VERSION "1.0"

NS_ :

BS_:

BU_: ECU1 ECU2

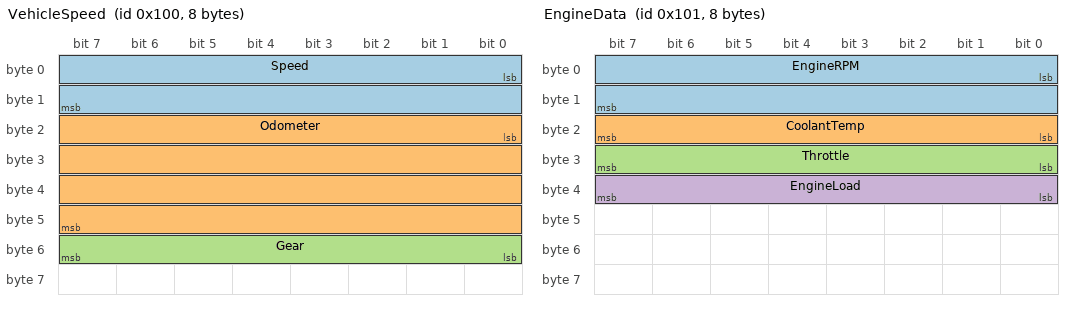
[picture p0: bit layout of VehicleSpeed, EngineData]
BO_ 256 VehicleSpeed: 8 ECU1
 SG_ Speed : 0|16@1+ (0.01,0) [0|655.35] "km/h" ECU2
 SG_ Odometer : 16|32@1+ (0.1,0) [0|429496729.5] "km" ECU2
 SG_ Gear : 48|8@1+ (1,0) [0|255] "" ECU2

BO_ 257 EngineData: 8 ECU1
 SG_ EngineRPM : 0|16@1+ (0.25,0) [0|16383.75] "rpm" ECU2
 SG_ CoolantTemp : 16|8@1- (1,-40) [-40|215] "degC" ECU2
 SG_ Throttle : 24|8@1+ (0.5,0) [0|127.5] "%" ECU2
 SG_ EngineLoad : 32|8@1+ (0.4,0) [0|102] "%" ECU2

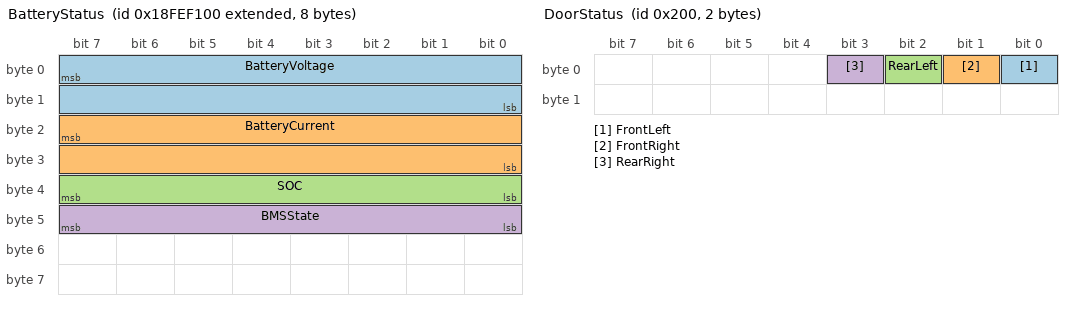
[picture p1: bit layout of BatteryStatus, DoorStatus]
BO_ 2566844672 BatteryStatus: 8 ECU1
 SG_ BatteryVoltage : 7|16@0+ (0.01,0) [0|655.35] "V" ECU2
 SG_ BatteryCurrent : 23|16@0- (0.1,0) [-3276.8|3276.7] "A" ECU2
 SG_ SOC : 32|8@1+ (1,0) [0|100] "%" ECU2
 SG_ BMSState : 40|8@1+ (1,0) [0|255] "" ECU2

BO_ 512 DoorStatus: 2 ECU1
 SG_ FrontLeft : 0|1@1+ (1,0) [0|1] "" ECU2
 SG_ FrontRight : 1|1@1+ (1,0) [0|1] "" ECU2
 SG_ RearLeft : 2|1@1+ (1,0) [0|1] "" ECU2
 SG_ RearRight : 3|1@1+ (1,0) [0|1] "" ECU2

BO_ 768 MuxExample: 8 ECU1
 SG_ Selector M : 0|8@1+ (1,0) [0|255] "" ECU2
 SG_ MuxA_Voltage m0 : 8|16@1+ (0.1,0) [0|6553.5] "V" ECU2
 SG_ MuxB_Count m1 : 8|16@1+ (1,0) [0|65535] "" ECU2

BO_ 1024 FdSensor: 12 ECU1
 SG_ FdValue : 0|32@1+ (0.001,0) [0|4294967.295] "V" ECU2
 SG_ FdCounter : 32|8@1+ (1,0) [0|255] "" ECU2

BO_ 1280 Fd64Array: 64 ECU1
 SG_ FD64_Ch00 : 0|8@1+ (1,0) [0|255] "" ECU2
 SG_ FD64_Ch01 : 8|8@1+ (1,0) [0|255] "" ECU2
 SG_ FD64_Ch02 : 16|8@1+ (1,0) [0|255] "" ECU2
 SG_ FD64_Ch03 : 24|8@1+ (1,0) [0|255] "" ECU2
 SG_ FD64_Ch04 : 32|8@1+ (1,0) [0|255] "" ECU2
 SG_ FD64_Ch05 : 40|8@1+ (1,0) [0|255] "" ECU2
 SG_ FD64_Ch06 : 48|8@1+ (1,0) [0|255] "" ECU2
 SG_ FD64_Ch07 : 56|8@1+ (1,0) [0|255] "" ECU2
 SG_ FD64_Ch08 : 64|8@1+ (1,0) [0|255] "" ECU2
 SG_ FD64_Ch09 : 72|8@1+ (1,0) [0|255] "" ECU2
 SG_ FD64_Ch10 : 80|8@1+ (1,0) [0|255] "" ECU2
 SG_ FD64_Ch11 : 88|8@1+ (1,0) [0|255] "" ECU2
 SG_ FD64_Ch12 : 96|8@1+ (1,0) [0|255] "" ECU2
 SG_ FD64_Ch13 : 104|8@1+ (1,0) [0|255] "" ECU2
 SG_ FD64_Ch14 : 112|8@1+ (1,0) [0|255] "" ECU2
 SG_ FD64_Ch15 : 120|8@1+ (1,0) [0|255] "" ECU2
 SG_ FD64_Ch16 : 128|8@1+ (1,0) [0|255] "" ECU2
 SG_ FD64_Ch17 : 136|8@1+ (1,0) [0|255] "" ECU2
 SG_ FD64_Ch18 : 144|8@1+ (1,0) [0|255] "" ECU2
 SG_ FD64_Ch19 : 152|8@1+ (1,0) [0|255] "" ECU2
 SG_ FD64_Ch20 : 160|8@1+ (1,0) [0|255] "" ECU2
 SG_ FD64_Ch21 : 168|8@1+ (1,0) [0|255] "" ECU2
 SG_ FD64_Ch22 : 176|8@1+ (1,0) [0|255] "" ECU2
 SG_ FD64_Ch23 : 184|8@1+ (1,0) [0|255] "" ECU2
 SG_ FD64_Ch24 : 192|8@1+ (1,0) [0|255] "" ECU2
 SG_ FD64_Ch25 : 200|8@1+ (1,0) [0|255] "" ECU2
 SG_ FD64_Ch26 : 208|8@1+ (1,0) [0|255] "" ECU2
 SG_ FD64_Ch27 : 216|8@1+ (1,0) [0|255] "" ECU2
 SG_ FD64_Ch28 : 224|8@1+ (1,0) [0|255] "" ECU2
 SG_ FD64_Ch29 : 232|8@1+ (1,0) [0|255] "" ECU2
 SG_ FD64_Ch30 : 240|8@1+ (1,0) [0|255] "" ECU2
 SG_ FD64_Ch31 : 248|8@1+ (1,0) [0|255] "" ECU2
 SG_ FD64_Ch32 : 256|8@1+ (1,0) [0|255] "" ECU2
 SG_ FD64_Ch33 : 264|8@1+ (1,0) [0|255] "" ECU2
 SG_ FD64_Ch34 : 272|8@1+ (1,0) [0|255] "" ECU2
 SG_ FD64_Ch35 : 280|8@1+ (1,0) [0|255] "" ECU2
 SG_ FD64_Ch36 : 288|8@1+ (1,0) [0|255] "" ECU2
 SG_ FD64_Ch37 : 296|8@1+ (1,0) [0|255] "" ECU2
 SG_ FD64_Ch38 : 304|8@1+ (1,0) [0|255] "" ECU2
 SG_ FD64_Ch39 : 312|8@1+ (1,0) [0|255] "" ECU2
 SG_ FD64_Ch40 : 320|8@1+ (1,0) [0|255] "" ECU2
 SG_ FD64_Ch41 : 328|8@1+ (1,0) [0|255] "" ECU2
 SG_ FD64_Ch42 : 336|8@1+ (1,0) [0|255] "" ECU2
 SG_ FD64_Ch43 : 344|8@1+ (1,0) [0|255] "" ECU2
 SG_ FD64_Ch44 : 352|8@1+ (1,0) [0|255] "" ECU2
 SG_ FD64_Ch45 : 360|8@1+ (1,0) [0|255] "" ECU2
 SG_ FD64_Ch46 : 368|8@1+ (1,0) [0|255] "" ECU2
 SG_ FD64_Ch47 : 376|8@1+ (1,0) [0|255] "" ECU2
 SG_ FD64_Ch48 : 384|8@1+ (1,0) [0|255] "" ECU2
 SG_ FD64_Ch49 : 392|8@1+ (1,0) [0|255] "" ECU2
 SG_ FD64_Ch50 : 400|8@1+ (1,0) [0|255] "" ECU2
 SG_ FD64_Ch51 : 408|8@1+ (1,0) [0|255] "" ECU2
 SG_ FD64_Ch52 : 416|8@1+ (1,0) [0|255] "" ECU2
 SG_ FD64_Ch53 : 424|8@1+ (1,0) [0|255] "" ECU2
 SG_ FD64_Ch54 : 432|8@1+ (1,0) [0|255] "" ECU2
 SG_ FD64_Ch55 : 440|8@1+ (1,0) [0|255] "" ECU2
 SG_ FD64_Voltage : 448|16@1+ (0.01,0) [0|655.35] "V" ECU2
 SG_ FD64_Current : 464|16@1+ (0.01,-100) [-100|555.35] "A" ECU2
 SG_ FD64_Temp : 480|16@1+ (0.1,-40) [-40|6553.1] "degC" ECU2
 SG_ FD64_Counter : 496|16@1+ (1,0) [0|65535] "" ECU2

CM_ BO_ 256 "Vehicle speed and odometer, 20ms cycle";
CM_ SG_ 256 Speed "Scaled speed signal";
CM_ SG_ 257 CoolantTemp "Signed temperature with -40 offset";
CM_ SG_ 2566844672 BatteryVoltage "Motorola 16-bit big-endian signal";
CM_ SG_ 768 Selector "Multiplexor: 0=Voltage, 1=Count";

CM_ BO_ 1280 "CAN FD 64-byte frame with 60 signals, 100ms cycle";
VAL_ 256 Gear 0 "P" 1 "R" 2 "N" 3 "D" ;
VAL_ 2566844672 BMSState 0 "Standby" 1 "Charging" 2 "Discharging" 3 "Fault" ;
